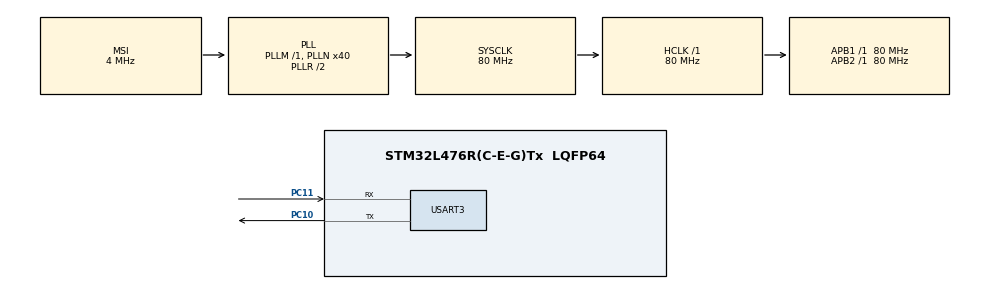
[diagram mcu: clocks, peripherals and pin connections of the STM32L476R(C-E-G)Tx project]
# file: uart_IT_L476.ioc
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Mcu.Family=STM32L4
NVIC.USART3_IRQn=true\:0\:0\:false\:false\:true\:true\:true
RCC.MSI_VALUE=4000000
PA14\ (JTCK-SWCLK).Mode=Trace_Asynchronous_SW
RCC.CortexFreq_Value=80000000
PH0-OSC_IN\ (PH0).Signal=RCC_OSC_IN
PC11.Signal=USART3_RX
PC10.Signal=USART3_TX
PC10.Mode=Asynchronous
PC15-OSC32_OUT\ (PC15).Signal=RCC_OSC32_OUT
PC15-OSC32_OUT\ (PC15).Mode=LSE-External-Oscillator
PH1-OSC_OUT\ (PH1).Signal=RCC_OSC_OUT
RCC.SYSCLKSource=RCC_SYSCLKSOURCE_PLLCLK
ProjectManager.StackSize=0x400
PB3\ (JTDO-TRACESWO).Signal=SYS_JTDO-SWO
PC14-OSC32_IN\ (PC14).Mode=LSE-External-Oscillator
USART3.VirtualMode-Asynchronous=VM_ASYNC
PA14\ (JTCK-SWCLK).Signal=SYS_JTCK-SWCLK
VP_SYS_VS_tim3.Mode=TIM3
ProjectManager.TargetToolchain=STM32CubeIDE
RCC.HCLKFreq_Value=80000000
RCC.APB2TimFreq_Value=80000000
RCC.USBFreq_Value=16000000
RCC.AHBFreq_Value=80000000
PH1-OSC_OUT\ (PH1).Mode=HSE-External-Oscillator
RCC.HSE_VALUE=8000000
board=custom
RCC.VCOOutputFreq_Value=160000000
NVIC.TIM3_IRQn=true\:0\:0\:false\:false\:true\:false\:true
RCC.APB2Freq_Value=80000000
PB3\ (JTDO-TRACESWO).Mode=Trace_Asynchronous_SW
RCC.ADCFreq_Value=16000000
Mcu.Name=STM32L476R(C-E-G)Tx
PA13\ (JTMS-SWDIO).Mode=Trace_Asynchronous_SW
RCC.SYSCLKFreq_VALUE=80000000
Mcu.Package=LQFP64
NVIC.TimeBase=TIM3_IRQn
PC14-OSC32_IN\ (PC14).Signal=RCC_OSC32_IN
NVIC.TimeBaseIP=TIM3
ProjectManager.HeapSize=0x200
PC11.Mode=Asynchronous
RCC.HSI_VALUE=16000000
NVIC.PriorityGroup=NVIC_PRIORITYGROUP_4
RCC.PLLN=40
RCC.APB1TimFreq_Value=80000000
PA13\ (JTMS-SWDIO).Signal=SYS_JTMS-SWDIO
RCC.APB1Freq_Value=80000000
PH0-OSC_IN\ (PH0).Mode=HSE-External-Oscillator
NVIC.RCC_IRQn=true\:0\:0\:false\:false\:true\:true\:false

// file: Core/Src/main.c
/* USER CODE BEGIN Header */
/**
  ******************************************************************************
  * @file           : main.c
  * @brief          : Main program body
  ******************************************************************************
  * @attention
  *
  * <h2><center>&copy; Copyright (c) 2021 STMicroelectronics.
  * All rights reserved.</center></h2>
  *
  * This software component is licensed by ST under BSD 3-Clause license,
  * the "License"; You may not use this file except in compliance with the
  * License. You may obtain a copy of the License at:
  *                        opensource.org/licenses/BSD-3-Clause
  *
  ******************************************************************************
  */
/* USER CODE END Header */
#include "main.h"

/* USER CODE BEGIN Includes */
#include <string.h> //strlen
#include <stdio.h> //printf
#include <stdlib.h> //printf

/* USER CODE END Includes */

UART_HandleTypeDef huart3;

void SystemClock_Config(void);
static void MX_GPIO_Init(void);
static void MX_USART3_UART_Init(void);

/* USER CODE BEGIN 0 */
int i=0,j=0,k=0;

char uart1_temp[1100],uart1_buf[1];
char uart3_temp[1100],uart3_buf[1];
char uart4_temp[1100],uart4_buf[1];

/* USER CODE END 0 */

int main(void)
{

  /* MCU Configuration--------------------------------------------------------*/

  /* Reset of all peripherals, Initializes the Flash interface and the Systick. */
  HAL_Init();

  /* Configure the system clock */
  SystemClock_Config();

  /* Initialize all configured peripherals */
  MX_GPIO_Init();
  MX_USART3_UART_Init();
  /* USER CODE BEGIN 2 */

  HAL_UART_Receive_IT(&huart3,(uint8_t *)uart3_buf,1);
  HAL_UART_Transmit(&huart3,"START\r\n",7,1000);
  HAL_Delay(1000);
  HAL_UART_Transmit(&huart3,"GO\r\n",4,1000);
  /* USER CODE END 2 */

  /* Infinite loop */
  while (1)
  {

  }
}

void SystemClock_Config(void)
{
  RCC_OscInitTypeDef RCC_OscInitStruct = {0};
  RCC_ClkInitTypeDef RCC_ClkInitStruct = {0};
  RCC_PeriphCLKInitTypeDef PeriphClkInit = {0};

  /** Configure LSE Drive Capability
  */
  HAL_PWR_EnableBkUpAccess();
  __HAL_RCC_LSEDRIVE_CONFIG(RCC_LSEDRIVE_LOW);
  /** Initializes the RCC Oscillators according to the specified parameters
  * in the RCC_OscInitTypeDef structure.
  */
  RCC_OscInitStruct.OscillatorType = RCC_OSCILLATORTYPE_LSE|RCC_OSCILLATORTYPE_MSI;
  RCC_OscInitStruct.LSEState = RCC_LSE_ON;
  RCC_OscInitStruct.MSIState = RCC_MSI_ON;
  RCC_OscInitStruct.MSICalibrationValue = 0;
  RCC_OscInitStruct.MSIClockRange = RCC_MSIRANGE_6;
  RCC_OscInitStruct.PLL.PLLState = RCC_PLL_ON;
  RCC_OscInitStruct.PLL.PLLSource = RCC_PLLSOURCE_MSI;
  RCC_OscInitStruct.PLL.PLLM = 1;
  RCC_OscInitStruct.PLL.PLLN = 40;
  RCC_OscInitStruct.PLL.PLLP = RCC_PLLP_DIV7;
  RCC_OscInitStruct.PLL.PLLQ = RCC_PLLQ_DIV2;
  RCC_OscInitStruct.PLL.PLLR = RCC_PLLR_DIV2;
  if (HAL_RCC_OscConfig(&RCC_OscInitStruct) != HAL_OK)
  {
    Error_Handler();
  }
  /** Initializes the CPU, AHB and APB buses clocks
  */
  RCC_ClkInitStruct.ClockType = RCC_CLOCKTYPE_HCLK|RCC_CLOCKTYPE_SYSCLK
                              |RCC_CLOCKTYPE_PCLK1|RCC_CLOCKTYPE_PCLK2;
  RCC_ClkInitStruct.SYSCLKSource = RCC_SYSCLKSOURCE_PLLCLK;
  RCC_ClkInitStruct.AHBCLKDivider = RCC_SYSCLK_DIV1;
  RCC_ClkInitStruct.APB1CLKDivider = RCC_HCLK_DIV1;
  RCC_ClkInitStruct.APB2CLKDivider = RCC_HCLK_DIV1;

  if (HAL_RCC_ClockConfig(&RCC_ClkInitStruct, FLASH_LATENCY_4) != HAL_OK)
  {
    Error_Handler();
  }
  PeriphClkInit.PeriphClockSelection = RCC_PERIPHCLK_USART3;
  PeriphClkInit.Usart3ClockSelection = RCC_USART3CLKSOURCE_PCLK1;
  if (HAL_RCCEx_PeriphCLKConfig(&PeriphClkInit) != HAL_OK)
  {
    Error_Handler();
  }
  /** Configure the main internal regulator output voltage
  */
  if (HAL_PWREx_ControlVoltageScaling(PWR_REGULATOR_VOLTAGE_SCALE1) != HAL_OK)
  {
    Error_Handler();
  }
  /** Enable MSI Auto calibration
  */
  HAL_RCCEx_EnableMSIPLLMode();
}

static void MX_USART3_UART_Init(void)
{

  huart3.Instance = USART3;
  huart3.Init.BaudRate = 115200;
  huart3.Init.WordLength = UART_WORDLENGTH_8B;
  huart3.Init.StopBits = UART_STOPBITS_1;
  huart3.Init.Parity = UART_PARITY_NONE;
  huart3.Init.Mode = UART_MODE_TX_RX;
  huart3.Init.HwFlowCtl = UART_HWCONTROL_NONE;
  huart3.Init.OverSampling = UART_OVERSAMPLING_16;
  huart3.Init.OneBitSampling = UART_ONE_BIT_SAMPLE_DISABLE;
  huart3.AdvancedInit.AdvFeatureInit = UART_ADVFEATURE_NO_INIT;
  if (HAL_UART_Init(&huart3) != HAL_OK)
  {
    Error_Handler();
  }

}

static void MX_GPIO_Init(void)
{

  /* GPIO Ports Clock Enable */
  __HAL_RCC_GPIOC_CLK_ENABLE();
  __HAL_RCC_GPIOH_CLK_ENABLE();
  __HAL_RCC_GPIOA_CLK_ENABLE();
  __HAL_RCC_GPIOB_CLK_ENABLE();

}

/* USER CODE BEGIN 4 */
void HAL_UART_RxCpltCallback(UART_HandleTypeDef *huart)
{
  /* Prevent unused argument(s) compilation warning */
//	if(huart == &huart3)
//	{
		uart3_temp[j]=uart3_buf[0]; //store byte in temp buffer
		if(uart3_temp[j]=='\n'){
//			printf(uart3_temp);
			HAL_UART_Transmit(&huart3,(uint8_t *)uart3_temp,j,200);
			memset(uart3_temp,0,strlen(uart3_temp));
			j=0;
		}
		else {
			j++;
		}
		HAL_UART_Receive_IT(&huart3,(uint8_t *)uart3_buf,1);
//	}
  /* NOTE : This function should not be modified, when the callback is needed,
            the HAL_UART_RxCpltCallback can be implemented in the user file.
   */
}
/* USER CODE END 4 */

 /**
  * @brief  Period elapsed callback in non blocking mode
  * @note   This function is called  when TIM3 interrupt took place, inside
  * HAL_TIM_IRQHandler(). It makes a direct call to HAL_IncTick() to increment
  * a global variable "uwTick" used as application time base.
  * @param  htim : TIM handle
  * @retval None
  */
void HAL_TIM_PeriodElapsedCallback(TIM_HandleTypeDef *htim)
{
  if (htim->Instance == TIM3) {
    HAL_IncTick();
  }
}

void Error_Handler(void)
{
  __disable_irq();
  while (1)
  {
  }
}

/************************ (C) COPYRIGHT STMicroelectronics *****END OF FILE****/
